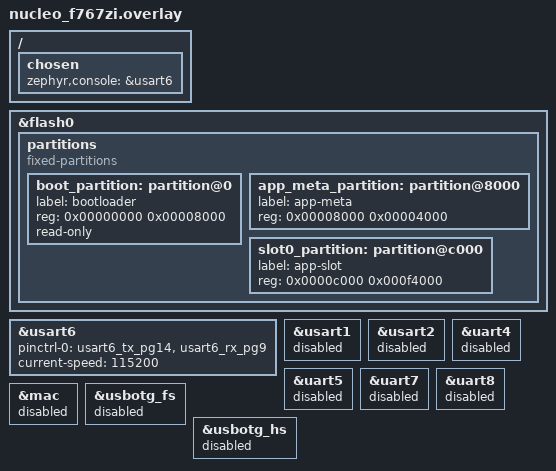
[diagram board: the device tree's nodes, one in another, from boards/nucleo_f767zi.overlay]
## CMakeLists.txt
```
#
# CMakeLists.txt - Zephyr demo application (ZDEMO), NUCLEO-F767ZI
#
# Author:  Sandesh Ghimire <sandesh@soccentric.com>
# Date:    2026-11-03
# SRS:     SRS-ZEPHYR-F767 (ZCON-001..003, ZGEN-001..007, ZLNK-001..004)
#
# Freestanding Zephyr application (ZCON-003): built against $ZEPHYR_BASE in
# the stm32-dev-zephyr container, without a west workspace.
#   scripts/build.sh [clean]
#

cmake_minimum_required(VERSION 3.20.0)

set(BOARD nucleo_f767zi)
set(DTC_OVERLAY_FILE "${CMAKE_CURRENT_SOURCE_DIR}/boards/nucleo_f767zi.overlay")

# --- Version and build metadata (ZGEN-002) ---------------------------------
file(STRINGS "${CMAKE_CURRENT_SOURCE_DIR}/VERSION" VERSION_LINES)
foreach(_line IN LISTS VERSION_LINES)
    if(_line MATCHES "^VERSION_MAJOR[ \t]*=[ \t]*([0-9]+)")
        set(APP_VERSION_MAJOR "${CMAKE_MATCH_1}")
    elseif(_line MATCHES "^VERSION_MINOR[ \t]*=[ \t]*([0-9]+)")
        set(APP_VERSION_MINOR "${CMAKE_MATCH_1}")
    elseif(_line MATCHES "^PATCHLEVEL[ \t]*=[ \t]*([0-9]+)")
        set(APP_VERSION_PATCH "${CMAKE_MATCH_1}")
    endif()
endforeach()
if(NOT DEFINED APP_VERSION_MAJOR)
    set(APP_VERSION_MAJOR 0)
endif()
if(NOT DEFINED APP_VERSION_MINOR)
    set(APP_VERSION_MINOR 1)
endif()
if(NOT DEFINED APP_VERSION_PATCH)
    set(APP_VERSION_PATCH 0)
endif()
set(APP_VERSION "${APP_VERSION_MAJOR}.${APP_VERSION_MINOR}.${APP_VERSION_PATCH}")
set(APP_FIRMWARE_NAME "zephyr-app")

execute_process(COMMAND git -C "${CMAKE_CURRENT_SOURCE_DIR}" rev-parse --short=12 HEAD
    OUTPUT_VARIABLE APP_GIT_COMMIT OUTPUT_STRIP_TRAILING_WHITESPACE ERROR_QUIET)
execute_process(COMMAND git -C "${CMAKE_CURRENT_SOURCE_DIR}" rev-parse HEAD
    OUTPUT_VARIABLE APP_GIT_COMMIT_FULL OUTPUT_STRIP_TRAILING_WHITESPACE ERROR_QUIET)
if(NOT APP_GIT_COMMIT)
    set(APP_GIT_COMMIT "unknown")
    set(APP_GIT_COMMIT_FULL "")
else()
    execute_process(COMMAND git -C "${CMAKE_CURRENT_SOURCE_DIR}" status --porcelain
        OUTPUT_VARIABLE APP_GIT_DIRTY OUTPUT_STRIP_TRAILING_WHITESPACE ERROR_QUIET)
    if(APP_GIT_DIRTY)
        string(APPEND APP_GIT_COMMIT "-dirty")
    endif()
endif()
string(TIMESTAMP APP_BUILD_DATE "%Y-%m-%d %H:%M:%S" UTC)
string(TIMESTAMP APP_BUILD_TIMESTAMP "%s" UTC)

# The image's Zephyr tree has no .git (ZCON-002); its version is recorded in
# /opt/zephyrproject/VERSION by docker/Dockerfile.
if(NOT DEFINED BUILD_VERSION AND EXISTS "$ENV{ZEPHYR_BASE}/../VERSION")
    file(STRINGS "$ENV{ZEPHYR_BASE}/../VERSION" BUILD_VERSION LIMIT_COUNT 1)
endif()

find_package(Zephyr REQUIRED HINTS $ENV{ZEPHYR_BASE})
project(zephyr_app LANGUAGES C)

target_compile_definitions(app PRIVATE
    APP_VERSION_STR="${APP_VERSION}"
    APP_FIRMWARE_NAME="${APP_FIRMWARE_NAME}"
    APP_GIT_COMMIT="${APP_GIT_COMMIT}"
    APP_BUILD_DATE="${APP_BUILD_DATE}"
    APP_BUILD_TIMESTAMP=${APP_BUILD_TIMESTAMP}
    APP_FLATCC_HEAP_SIZE=12288
    FLATCC_ALLOC=app_flatcc_alloc
    FLATCC_FREE=app_flatcc_free
    FLATCC_REALLOC=app_flatcc_realloc
    FLATCC_CALLOC=app_flatcc_calloc
    FLATCC_ALIGNED_ALLOC=app_flatcc_aligned_alloc
    FLATCC_ALIGNED_FREE=app_flatcc_aligned_free
    FLATCC_EMITTER_ALLOC=app_flatcc_alloc
    FLATCC_EMITTER_FREE=app_flatcc_free)

# The generated flatcc headers and runtime see the fixed-arena allocator
# through this force-include (ZRT-004).
target_compile_options(app PRIVATE
    -include "${CMAKE_CURRENT_SOURCE_DIR}/src/comms/flatcc_port.h")

target_include_directories(app PRIVATE
    "${CMAKE_CURRENT_SOURCE_DIR}/src"
    "${CMAKE_BINARY_DIR}/generated"
    "${CMAKE_CURRENT_SOURCE_DIR}/src/generated"
    "${CMAKE_CURRENT_SOURCE_DIR}/third_party/flatcc/include")

# The generated flatcc headers use compact macro formatting that trips
# -Wmisleading-indentation in the one translation unit that includes them.
set_source_files_properties(src/comms/comms.c PROPERTIES
    COMPILE_OPTIONS "-Wno-misleading-indentation")

target_sources(app PRIVATE
    # Application entry point and shared configuration
    src/main.c

    # Board-level I/O
    src/board/button.c
    src/board/led.c

    # Bootloader contract and metadata
    src/boot/flash_confirm.c
    src/boot/handover.c
    src/boot/identity.c

    # HWLINK communication stack
    src/comms/comms.c
    src/comms/flatcc_port.c
    src/comms/hwlink.c
    src/comms/uart_hwlink.c

    # System services and supervision
    src/system/debug_log.c
    src/system/fatal.c
    src/system/health.c
    src/system/iwdg.c
    src/system/reset_cause.c)

# flatcc 0.6.1 runtime as released.  Only builder, verifier and emitter are
# linked; JSON support is not used.
set(FLATCC_ROOT "${CMAKE_CURRENT_SOURCE_DIR}/third_party/flatcc")
target_sources(app PRIVATE
    "${FLATCC_ROOT}/src/runtime/builder.c"
    "${FLATCC_ROOT}/src/runtime/verifier.c"
    "${FLATCC_ROOT}/src/runtime/emitter.c"
    "${FLATCC_ROOT}/src/runtime/refmap.c")

# --- HWLINK schema (ZLNK-001) ------------------------------------------------
# The generated C headers are committed so the container does not need a host
# flatcc compiler.  When flatcc is available, regenerate them as part of the
# build; the build-tree copy takes precedence over src/generated.
find_program(FLATCC flatcc)
if(FLATCC)
    set(FLATCC_OUT "${CMAKE_BINARY_DIR}/generated")
    add_custom_command(
        OUTPUT
            "${FLATCC_OUT}/hwlink_reader.h"
            "${FLATCC_OUT}/hwlink_builder.h"
            "${FLATCC_OUT}/hwlink_verifier.h"
            "${FLATCC_OUT}/flatbuffers_common_reader.h"
            "${FLATCC_OUT}/flatbuffers_common_builder.h"
        COMMAND ${CMAKE_COMMAND} -E make_directory "${FLATCC_OUT}"
        COMMAND ${FLATCC} -a -o "${FLATCC_OUT}" "${CMAKE_CURRENT_SOURCE_DIR}/protocol/hwlink.fbs"
        DEPENDS "${CMAKE_CURRENT_SOURCE_DIR}/protocol/hwlink.fbs"
        COMMENT "Generating HWLINK FlatBuffers C headers")
    add_custom_target(hwlink_schema DEPENDS
        "${FLATCC_OUT}/hwlink_reader.h"
        "${FLATCC_OUT}/hwlink_builder.h"
        "${FLATCC_OUT}/hwlink_verifier.h")
    add_dependencies(app hwlink_schema)
endif()

# --- Build products (ZGEN-001, ZGEN-002) -------------------------------------
find_package(Python3 COMPONENTS Interpreter REQUIRED)
get_filename_component(_compiler_dir "${CMAKE_C_COMPILER}" DIRECTORY)
find_program(SIZE_TOOL NAMES arm-zephyr-eabi-size arm-none-eabi-size
    HINTS "${_compiler_dir}" REQUIRED)

add_custom_target(zephyr_app_outputs ALL
    COMMAND ${CMAKE_COMMAND} -E copy
            "${CMAKE_BINARY_DIR}/zephyr/zephyr.elf"
            "${CMAKE_BINARY_DIR}/zephyr-app.elf"
    COMMAND ${CMAKE_COMMAND} -E copy
            "${CMAKE_BINARY_DIR}/zephyr/zephyr.bin"
            "${CMAKE_BINARY_DIR}/zephyr-app.bin"
    COMMAND ${CMAKE_COMMAND} -E copy
            "${CMAKE_BINARY_DIR}/zephyr/zephyr.hex"
            "${CMAKE_BINARY_DIR}/zephyr-app.hex"
    COMMAND ${CMAKE_COMMAND} -E copy
            "${CMAKE_BINARY_DIR}/zephyr/zephyr.map"
            "${CMAKE_BINARY_DIR}/zephyr-app.map"
    COMMAND ${Python3_EXECUTABLE} "${CMAKE_CURRENT_SOURCE_DIR}/scripts/mkimage.py"
            --input "${CMAKE_BINARY_DIR}/zephyr-app.bin"
            --output "${CMAKE_BINARY_DIR}/zephyr-app.img"
            --version "${APP_VERSION}"
            --commit "${APP_GIT_COMMIT_FULL}"
            --timestamp "${APP_BUILD_TIMESTAMP}"
            --name "${APP_FIRMWARE_NAME}"
    COMMAND ${Python3_EXECUTABLE} "${CMAKE_CURRENT_SOURCE_DIR}/scripts/check_footprint.py"
            --size-tool "${SIZE_TOOL}"
            --max-flash 131072
            --max-ram 65536
            "${CMAKE_BINARY_DIR}/zephyr-app.elf"
    DEPENDS zephyr_final
    BYPRODUCTS
        "${CMAKE_BINARY_DIR}/zephyr-app.elf"
        "${CMAKE_BINARY_DIR}/zephyr-app.bin"
        "${CMAKE_BINARY_DIR}/zephyr-app.hex"
        "${CMAKE_BINARY_DIR}/zephyr-app.map"
        "${CMAKE_BINARY_DIR}/zephyr-app.img"
    COMMENT "Copying zephyr-app.* and generating the BOOT image file")
```

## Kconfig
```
#
# Kconfig - ZDEMO application options
#
# Author:  Sandesh Ghimire <sandesh@soccentric.com>
# Date:    2026-11-03
# Target:  NUCLEO-F767ZI
# SRS:     ZFN-004 (HLT-004)
#

mainmenu "Zephyr demo application (ZDEMO)"

config ZDEMO_FAIL_HEALTH
	bool "Force the pending-slot health check to fail"
	default n
	help
	  Build the equivalent of the C demo's DEMO_FAIL_HEALTH option.  A
	  pending slot never confirms, LD3 fast-blinks, and the watchdog is
	  stopped after 10 s so BOOT can count a failed trial and roll back.

source "Kconfig.zephyr"
```

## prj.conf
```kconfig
# prj.conf - ZDEMO Kconfig
# Author: Sandesh Ghimire <sandesh@soccentric.com>
# SRS:    SRS-ZEPHYR-F767

# ZBT-001: run from the bootloader slot at 0x0800C000, 976 KB.
CONFIG_USE_DT_CODE_PARTITION=n
CONFIG_FLASH_LOAD_OFFSET=0xC000
CONFIG_FLASH_LOAD_SIZE=0xF4000

# ZRT-002: k_event is used for health check-ins.
CONFIG_EVENTS=y

# ZRT-003: 1 kHz kernel tick.
CONFIG_SYS_CLOCK_TICKS_PER_SEC=1000

# ZGEN-003: caches on, as in the C demo.
CONFIG_CACHE_MANAGEMENT=y
CONFIG_ICACHE=y
CONFIG_DCACHE=y

# ZRT-006 / ZSAFE-004: MPU stack guards and assertions.
CONFIG_HW_STACK_PROTECTION=y
CONFIG_ASSERT=y

# ZGEN-006: no warnings.
CONFIG_COMPILER_WARNINGS_AS_ERRORS=y

# LEDs, button and USART3.
CONFIG_GPIO=y
CONFIG_SERIAL=y
CONFIG_UART_INTERRUPT_DRIVEN=y
CONFIG_UART_USE_RUNTIME_CONFIGURE=y

# ZCON-005: USART3 carries HWLINK only.  ZDBG-001: console and log output
# go to USART6 instead (chosen zephyr,console in the board overlay).
CONFIG_CONSOLE=y
CONFIG_UART_CONSOLE=y
CONFIG_PRINTK=y
CONFIG_BOOT_BANNER=n

# ZDBG-002: deferred logging, so no thread waits on the debug UART;
# ZDBG-003: src/system/debug_log.c prints the family line format.
CONFIG_LOG=y
CONFIG_LOG_MODE_DEFERRED=y
CONFIG_LOG_BACKEND_UART=y
CONFIG_LOG_OUTPUT=y
CONFIG_LOG_CUSTOM_FORMAT_SUPPORT=y
CONFIG_LOG_BACKEND_UART_OUTPUT_CUSTOM=y
CONFIG_LOG_DEFAULT_LEVEL=3
CONFIG_LOG_BUFFER_SIZE=1024

# ZGEN-004: fatal errors reset the board.
CONFIG_REBOOT=y

# ZGEN-005: reset cause through hwinfo.
CONFIG_HWINFO=y

# ZBT-006 / ZFN-004: Zephyr flash API for the CONFIRMED record.
CONFIG_FLASH=y

# ZRT-004 / ZFN-004: IWDG through the watchdog API.
CONFIG_WATCHDOG=y

# ZLNK-002: Zephyr CRC32-ISO-HDLC.
CONFIG_CRC=y

# ZRT-005: high-water marks for Status.
CONFIG_THREAD_MONITOR=y
CONFIG_INIT_STACKS=y
CONFIG_THREAD_STACK_INFO=y
CONFIG_THREAD_NAME=y

# Heap statistics for Status (the application itself does not allocate).

# Keep the main thread small; all work is in the static application threads.
CONFIG_MAIN_STACK_SIZE=2048
CONFIG_BOOT_BANNER=n
```

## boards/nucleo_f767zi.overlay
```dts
/*
 * nucleo_f767zi.overlay - NUCLEO-F767ZI flash layout for the project A/B bootloader
 *
 * Author:  Sandesh Ghimire <sandesh@soccentric.com>
 * Date:    2026-11-03
 * Target:  NUCLEO-F767ZI
 * SRS:     ZBT-001, ZBT-006, ZSAFE-001/003, ZDBG-001
 *
 * The board devicetree describes an MCUboot-style layout.  ZDEMO uses the
 * project bootloader layout instead (SRS-BOOT-F767 section 3):
 *
 *   0x08000000  bootloader, sectors 0-1, 32 KB, read-only
 *   0x08008000  metadata, sector 2, 16 KB
 *   0x0800C000  application slot, sectors 3-11, 976 KB
 *
 * Bank swapping maps either bank at 0x08000000, so the same overlay and
 * image work for slot A and slot B.
 */

/delete-node/ &boot_partition;
/delete-node/ &storage_partition;
/delete-node/ &slot0_partition;
/delete-node/ &slot1_partition;
/delete-node/ &scratch_partition;

&flash0 {
	partitions {
		compatible = "fixed-partitions";
		#address-cells = <1>;
		#size-cells = <1>;

		boot_partition: partition@0 {
			label = "bootloader";
			reg = <0x00000000 0x00008000>;
			read-only;
		};

		app_meta_partition: partition@8000 {
			label = "app-meta";
			reg = <0x00008000 0x00004000>;
		};

		slot0_partition: partition@c000 {
			label = "app-slot";
			reg = <0x0000c000 0x000f4000>;
		};
	};
};

/* ZDBG-001: console and log output on USART6 (PG14 = Arduino D1 TX,
 * PG9 = D0 RX), 115200 8N1.  HWLINK keeps USART3 to itself. */
/ {
	chosen {
		zephyr,console = &usart6;
	};
};

&usart6 {
	pinctrl-0 = <&usart6_tx_pg14 &usart6_rx_pg9>;
	pinctrl-names = "default";
	current-speed = <115200>;
	status = "okay";
};

/* ZSAFE-003: only the LEDs, B1, USART3 (HWLINK) and USART6 (debug) are
 * used. */
&usart1 {
	status = "disabled";
};

&usart2 {
	status = "disabled";
};

&uart4 {
	status = "disabled";
};

&uart5 {
	status = "disabled";
};

&uart7 {
	status = "disabled";
};

&uart8 {
	status = "disabled";
};

&mac {
	status = "disabled";
};

&usbotg_fs {
	status = "disabled";
};

&usbotg_hs {
	status = "disabled";
};
```

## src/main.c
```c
/*
 * main.c - Zephyr demo application entry point
 *
 * Author:  Sandesh Ghimire <sandesh@soccentric.com>
 * Date:    2026-11-03
 * Target:  NUCLEO-F767ZI (Zephyr board nucleo_f767zi), started by BOOT
 * SRS:     SRS-ZEPHYR-F767: ZBT-001..005, ZGEN-003..005, ZRT-001..006,
 *          ZFN-001..005, ZSAFE-001..004
 *
 * The four application threads (Health, Comms, Button, LED) are statically
 * defined.  main() only performs the reset-safe early start-up sequence and
 * then returns; Zephyr keeps running the application threads.
 */

#include <soc.h>
#include <zephyr/kernel.h>
#include <zephyr/logging/log.h>

#include "app/zdemo.h"
#include "board/led.h"
#include "boot/boot_contract.h"
#include "boot/handover.h"
#include "comms/uart_hwlink.h"
#include "system/app_fault.h"
#include "system/health.h"
#include "system/iwdg.h"
#include "system/reset_cause.h"

LOG_MODULE_DECLARE(app);

BUILD_ASSERT(CONFIG_FLASH_LOAD_OFFSET == 0xC000,
	     "ZBT-001: the application must be linked at 0x0800C000");
BUILD_ASSERT(CONFIG_FLASH_LOAD_SIZE == 0xF4000,
	     "ZBT-001: the application slot is 976 KB");

/**
 * @brief Report heap usage for Status / health purposes.
 *
 * This application is heapless: flatcc uses a fixed static arena and
 * malloc/free are not linked. Reporting a private unused heap would
 * make the Status and health figures meaningless, so both are reported
 * as zero.
 *
 * @param free_bytes   Receives 0 (no heap).
 * @param min_free_bytes Receives 0 (no heap).
 */
void app_heap_stats(uint32_t *free_bytes, uint32_t *min_free_bytes)
{
	*free_bytes = 0U;
	*min_free_bytes = 0U;
}

/**
 * @brief Zephyr application entry point: early start-up sequence.
 *
 * Performs the reset-safe early start-up only (fault record stamp, early
 * watchdog feed, reset-cause capture, hand-over decode, VTOR check,
 * second watchdog feed, LED error latch, UART bring-up) and then returns;
 * Zephyr keeps the statically defined application threads running.
 *
 * @return 0 on success.
 */
int main(void)
{
	/* The fault record is in no-init RAM; bump its boot id first. */
	app_fault_boot_start();

	/* ZBT-002/APP-004: feed the watchdog BOOT started as early as
	 * possible, before any long initialisation. */
	app_wdt_feed();

	/* ZGEN-005: keep the reset cause for Status, then clear it. */
	app_reset_cause_capture();

	/* ZBT-004: decode the hand-over record before Health starts. */
	app_handover_read();

	/* ZDBG-001: start-up line on the debug UART. */
	LOG_INF("start v%s %s, slot %c %s, reset %s", APP_VERSION_STR,
		APP_GIT_COMMIT,
		g_handover.slot == APP_SLOT_A ? 'A' :
		g_handover.slot == APP_SLOT_B ? 'B' : '?',
		g_handover.trial == 2U ? "on trial" :
		g_handover.trial == 1U ? "confirmed" : "no hand-over",
		app_reset_cause_text);

	/* ZBT-001/ZBT-002: the vector table must be the image's own table. */
	if (SCB->VTOR != (0x08000000UL + CONFIG_FLASH_LOAD_OFFSET)) {
		k_panic();
	}

	(void)app_wdt_init();

	/* LED-005: latch LD3 for the last fault or watchdog reset. */
	if (app_fault_is_valid()) {
		(void)led_post_error(APP_ERROR_FAULT);
		LOG_WRN("last fault recorded before this reset");
	}
	if (app_reset_was_error()) {
		(void)led_post_error(APP_ERROR_WATCHDOG);
	}

	/* COM-001/002: USART3 must be running before the health check. */
	if (!hwlink_uart_init()) {
		k_panic();
	}

	return 0;
}
```

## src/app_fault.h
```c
/*
 * app_fault.h - no-init fault record and fatal paths
 *
 * Author:  Sandesh Ghimire <sandesh@soccentric.com>
 * Date:    2026-11-03
 * Target:  NUCLEO-F767ZI
 * SRS:     ZGEN-004 (DGEN-004), ZSAFE-004
 */

#ifndef ZDEMO_APP_FAULT_H
#define ZDEMO_APP_FAULT_H

#include <stdbool.h>
#include <stdint.h>

/** Magic value ('FAUL') identifying a valid non-volatile fault record. */
#define APP_FAULT_MAGIC          0x4641554CUL  /* "FAUL" */
/** Maximum length (including NUL) of the stored task name. */
#define APP_FAULT_TASK_LEN       16U
/** Maximum length (including NUL) of the stored source file name. */
#define APP_FAULT_FILE_LEN       32U

/**
 * @brief Reason categories for a fatal fault captured by this module.
 *
 * The reason is recorded in @ref app_fault_record_t so the reason can be
 * inspected on the following boot.
 */
typedef enum {
    APP_FAULT_NONE = 0,
    APP_FAULT_HARDFAULT,
    APP_FAULT_MEMMANAGE,
    APP_FAULT_BUSFAULT,
    APP_FAULT_USAGEFAULT,
    APP_FAULT_ASSERT,
    APP_FAULT_STACK_OVERFLOW,
    APP_FAULT_MALLOC_FAILED,
    APP_FAULT_STARTUP
} app_fault_reason_t;

/**
 * @brief No-init persistent record of the last fatal fault.
 *
 * Stored in no-init RAM so the record survives a reset. The \c magic
 * field distinguishes a valid record from power-on garbage.
 *
 * @note Do not reorder members without updating the reader/writer side;
 *       the record is consumed by the boot monitor for diagnostics.
 */
typedef struct {
    uint32_t magic;
    uint32_t reason;
    uint32_t cfsr;
    uint32_t hfsr;
    uint32_t mmfar;
    uint32_t bfar;
    uint32_t pc;
    uint32_t lr;
    uint32_t psr;
    uint32_t line;
    uint32_t boot_id;
    char task[APP_FAULT_TASK_LEN];
    char file[APP_FAULT_FILE_LEN];
} app_fault_record_t;

/** Persistent no-init fault record, shared with the fault capture code. */
extern app_fault_record_t g_app_fault;

/**
 * @brief Called at boot start to stamp this boot into the fault record.
 */
void app_fault_boot_start(void);

/**
 * @brief Check whether the fault record holds a valid (magic-checked) entry.
 *
 * @return true if the record magic is valid, false otherwise.
 */
bool app_fault_is_valid(void);

/**
 * @brief Check whether the recorded fault belongs to the current boot.
 *
 * @return true if the record was written during the running boot.
 */
bool app_fault_is_current_boot(void);

/**
 * @brief Check whether the recorded fault is from the previous boot.
 *
 * @return true if the record was written during the boot before this one.
 */
bool app_fault_is_previous_boot(void);

/**
 * @brief Convert a fault reason into a human-readable string.
 *
 * @param reason Fault reason to convert.
 * @return NUL-terminated, read-only description of @p reason.
 */
const char *app_fault_reason_text(app_fault_reason_t reason);

/**
 * @brief Get the task name stored in the fault record.
 *
 * @return NUL-terminated task name (may be empty).
 */
const char *app_fault_task(void);

/**
 * @brief Get the source file name stored in the fault record.
 *
 * @return NUL-terminated file name (may be empty).
 */
const char *app_fault_file(void);

/**
 * @brief Erase the fault record (clears magic and stored data).
 */
void app_fault_clear(void);

#endif /* ZDEMO_APP_FAULT_H */
```

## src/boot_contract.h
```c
/*
 * boot_contract.h - flash layout, hand-over and metadata contract with BOOT
 *
 * Author:  Sandesh Ghimire <sandesh@soccentric.com>
 * Date:    2026-11-03
 * Target:  STM32F767ZIT6, dual-bank flash (nDBANK = 0)
 * SRS:     DBT-001, DBT-004, DBT-005, DBT-006, HLT-002, DSAFE-002
 *
 * The values in this file mirror SRS-BOOT-F767 LAY-001..LAY-005, HND-003 and
 * Appendix B.  DEMO only ever reads the slot metadata and programs the one
 * CONFIRMED record.
 */

#ifndef BOOT_CONTRACT_H
#define BOOT_CONTRACT_H

#include <stdint.h>

/* LAY-002: every application is linked at the slot offset in bank 1.  BOOT
 * maps the active bank at 0x08000000 with SYSCFG_MEMRMP.SWP_FB, so the same
 * image runs from slot A and slot B. */
/** Base address of the application slot in bank 1 (LAY-002). */
#define APP_SLOT_BASE           0x0800C000UL
/** Size of one application slot: 976 KB. */
#define APP_SLOT_SIZE           0x000F4000UL   /* 976 KB */

/** Size of one flash bank (1 MB). */
#define APP_BANK_SIZE           0x00100000UL
/** Offset of the slot metadata sector within a bank. */
#define APP_META_OFFSET         0x00008000UL
/** Size of the slot metadata sector (16 KB). */
#define APP_META_SIZE           0x00004000UL

/* Physical addresses without bank swap (what BOOT uses while it runs). */
/** Slot A metadata address, physical (no bank swap). */
#define APP_META_A_ADDR         0x08008000UL
/** Slot B metadata address, physical (no bank swap). */
#define APP_META_B_ADDR         0x08108000UL

/* While an application runs, SYSCFG_MEMRMP.SWP_FB maps its own bank to
 * 0x08000000, so its metadata sector is always visible at this alias. */
/** Bank-alias address at which a running app sees its own metadata sector. */
#define APP_RUNNING_META_ADDR   0x08008000UL

/* Appendix B record offsets and magic words (little-endian). */
/** Offset of the metadata header record. */
#define APP_META_HEADER_OFFSET    0x000U
/** Offset of the VERIFIED state record. */
#define APP_META_VERIFIED_OFFSET  0x100U
/** Offset of the ACTIVATED state record. */
#define APP_META_ACTIVATED_OFFSET 0x120U
/** Offset of the CONFIRMED state record (the only one DEMO programs). */
#define APP_META_CONFIRMED_OFFSET 0x140U
/** Offset of the REJECTED state record. */
#define APP_META_REJECTED_OFFSET  0x160U
/** Size of one metadata state record, in bytes. */
#define APP_META_RECORD_SIZE      32U

/** Magic word ('VERI') identifying a VERIFIED record. */
#define APP_META_VERIFIED_MAGIC   0x56455249UL  /* "VERI" */
/** Magic word ('ACTV') identifying an ACTIVATED record. */
#define APP_META_ACTIVATED_MAGIC  0x41435456UL  /* "ACTV" */
/** Magic word ('CONF') identifying a CONFIRMED record. */
#define APP_META_CONFIRMED_MAGIC  0x434F4E46UL  /* "CONF" */
/** Magic word ('REJE') identifying a REJECTED record. */
#define APP_META_REJECTED_MAGIC   0x52454A45UL  /* "REJE" */

/** Absolute address of the CONFIRMED record for a running app. */
#define APP_CONFIRMED_ADDR \
    (APP_RUNNING_META_ADDR + APP_META_CONFIRMED_OFFSET)

/* Hand-over record in RTC_BKP2R (HND-003).  The low 24 bits are the magic
 * and the upper byte carries the slot and trial state:
 *
 *   bits  0..23  magic 0x444E48 (the bytes "HND")
 *   bits 24..25  slot: 1 = A, 2 = B, 0 = unknown
 *   bit  26      trial pending
 *   bits 27..28  trial counter (0..3)
 *
 * The exact packing is private to the BOOT/DEMO pair; BOOT writes the same
 * word.  A missing record (no BOOT) reads as erased/zero and is reported as
 * slot UNKNOWN (DBT-004). */
/** Hand-over magic (bytes "HND") in the low 24 bits of RTC_BKP2R. */
#define APP_HANDOVER_MAGIC        0x00444E48UL  /* bytes "HND", 0 */
/** Mask selecting the 24-bit hand-over magic field. */
#define APP_HANDOVER_MAGIC_MASK   0x00FFFFFFUL
/** Bit shift of the slot field (1 = A, 2 = B) in the hand-over word. */
#define APP_HANDOVER_SLOT_SHIFT   24U
/** Mask of the slot field within its bit pair. */
#define APP_HANDOVER_SLOT_MASK    0x3UL
/** Bit selecting "trial pending" in the hand-over word. */
#define APP_HANDOVER_PENDING_BIT  26U
/** Bit shift of the 2-bit trial counter (0..3). */
#define APP_HANDOVER_TRIAL_SHIFT  27U
/** Mask of the trial counter field within its two bits. */
#define APP_HANDOVER_TRIAL_MASK   0x3UL

/* RTC_BKP1R "stay in BOOT" request (ENT-002). */
/** Magic word (bytes "STAY") in RTC_BKP1R requesting reboot into BOOT. */
#define APP_STAY_IN_BOOT_MAGIC    0x59415453UL  /* bytes "STAY" */

/* Slot identifiers shared with Status. */
/** Slot value meaning "unknown / no hand-over record". */
#define APP_SLOT_UNKNOWN          0U
/** Slot value for flash slot A. */
#define APP_SLOT_A                1U
/** Slot value for flash slot B. */
#define APP_SLOT_B                2U

#endif /* BOOT_CONTRACT_H */
```

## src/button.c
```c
/*
 * button.c - user button B1 (PC13), GPIO interrupt + 30 ms debounce
 *
 * Author:  Sandesh Ghimire <sandesh@soccentric.com>
 * Date:    2026-11-03
 * Target:  NUCLEO-F767ZI
 * SRS:     ZFN-002 (BTN-001..BTN-004)
 *
 * B1 is physically high when pressed.  The GPIO interrupt only wakes the
 * thread; debounce and short/long classification use absolute uptime.  The
 * LED thread owns the pattern state, so this thread posts a button message.
 */

#include <zephyr/device.h>
#include <zephyr/drivers/gpio.h>
#include <zephyr/kernel.h>

#include "button.h"
#include "health.h"
#include "led.h"
#include "zdemo.h"
#include "zdemo_threads.h"

/* Debounce window a raw level must hold before it counts as a change. */
#define BUTTON_DEBOUNCE_MS  30U
/* Presses shorter than this (and released) are reported as short presses. */
#define BUTTON_SHORT_MAX_MS 1000U
/* Presses held at least this long are reported as long presses. */
#define BUTTON_LONG_MS      2000U
/* Interval between button-thread check-ins to the health monitor. */
#define BUTTON_CHECKIN_MS   500U
/* Maximum time the thread sleeps on the wake semaphore. */
#define BUTTON_POLL_MS      10U

/** Device-tree descriptor of the user button (alias sw0). */
static const struct gpio_dt_spec button =
	GPIO_DT_SPEC_GET(DT_ALIAS(sw0), gpios);
/** GPIO callback context for the button interrupt. */
static struct gpio_callback button_cb;
/** Semaphore signalled by the button ISR to wake the thread. */
static K_SEM_DEFINE(button_sem, 0, 1);

/**
 * @brief Read the raw, un-debounced level of the button pin.
 *
 * @return true if the pin reads high (button physically pressed),
 *         false if low.
 */
static bool button_raw(void)
{
	return gpio_pin_get_raw(button.port, button.pin) > 0;
}

/**
 * @brief GPIO interrupt handler for the button.
 *
 * Only wakes the button thread; all debounce and press classification is
 * done in thread context.
 */
static void button_isr(const struct device *port, struct gpio_callback *cb,
		       gpio_port_pins_t pins)
{
	ARG_UNUSED(port);
	ARG_UNUSED(cb);
	ARG_UNUSED(pins);

	k_sem_give(&button_sem);
}

/**
 * @brief Button debounce and short/long press classification thread.
 *
 * Wakes on the button ISR semaphore (with a polling fallback), debounces
 * the raw pin level, and posts a message to the LED thread on release:
 * - short press: release after less than 1 s
 * - long press:  held for at least 2 s (posted once, while held)
 *
 * Also check-ins with the health monitor periodically.
 */
static void button_thread(void *p1, void *p2, void *p3)
{
	ARG_UNUSED(p1);
	ARG_UNUSED(p2);
	ARG_UNUSED(p3);

	(void)k_thread_name_set(k_current_get(), "Button");

	if (!gpio_is_ready_dt(&button) ||
	    gpio_pin_configure_dt(&button, GPIO_INPUT | GPIO_PULL_DOWN) != 0) {
		k_panic();
	}

	gpio_init_callback(&button_cb, button_isr, BIT(button.pin));
	if (gpio_add_callback_dt(&button, &button_cb) != 0 ||
	    gpio_pin_interrupt_configure_dt(&button, GPIO_INT_EDGE_BOTH) != 0) {
		k_panic();
	}

	uint32_t now = k_uptime_get_32();
	bool stable = button_raw();
	bool candidate = stable;
	uint32_t candidate_since = now;
	uint32_t press_start = now;
	bool pressed = stable;
	bool long_sent = false;
	uint32_t last_checkin = now;

	for (;;) {
		(void)k_sem_take(&button_sem, K_MSEC(BUTTON_POLL_MS));
		now = k_uptime_get_32();
		bool raw = button_raw();

		if (raw != candidate) {
			candidate = raw;
			candidate_since = now;
		} else if (candidate != stable &&
			   (now - candidate_since) >= BUTTON_DEBOUNCE_MS) {
			stable = candidate;
			if (stable) {
				pressed = true;
				long_sent = false;
				press_start = now;
			} else {
				uint32_t duration = now - press_start;

				if (pressed && !long_sent) {
					if (duration < BUTTON_SHORT_MAX_MS) {
						(void)led_post_button(1U);
					} else if (duration >= BUTTON_LONG_MS) {
						(void)led_post_button(2U);
					}
				}
				pressed = false;
			}
		}

		if (pressed && !long_sent &&
		    (now - press_start) >= BUTTON_LONG_MS) {
			long_sent = true;
			(void)led_post_button(2U);
		}

		if ((now - last_checkin) >= BUTTON_CHECKIN_MS) {
			health_checkin(HEALTH_TASK_BUTTON);
			last_checkin = now;
		}
	}
}

/* Button thread: debounce + short/long press detection. */
K_THREAD_DEFINE(zdemo_button_thread, ZDEMO_BUTTON_STACK, button_thread, NULL,
		NULL, NULL, ZDEMO_PRIO_BUTTON, 0, 0);
```

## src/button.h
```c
/*
 * button.h - user button B1 (PC13), GPIO interrupt + 30 ms debounce
 *
 * Author:  Sandesh Ghimire <sandesh@soccentric.com>
 * Date:    2026-11-03
 * Target:  NUCLEO-F767ZI
 * SRS:     ZFN-002 (BTN-001..BTN-004)
 */

/**
 * @file button.h
 * @brief Public interface placeholder for user button B1 (PC13).
 *
 * The button driver (implementation in button.c) handles GPIO interrupt
 * and 30 ms debounce internally and communicates with other threads
 * through the LED message queue, so this header currently exposes no
 * public API.
 */
#ifndef ZDEMO_BUTTON_H
#define ZDEMO_BUTTON_H

#endif /* ZDEMO_BUTTON_H */
```

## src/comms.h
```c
/*
 * comms.h - HWLINK Comms thread
 *
 * Author:  Sandesh Ghimire <sandesh@soccentric.com>
 * Date:    2026-11-03
 * Target:  NUCLEO-F767ZI
 * SRS:     ZFN-003 (COM-001..COM-007), ZFN-005
 */

#ifndef ZDEMO_COMMS_H
#define ZDEMO_COMMS_H

#include <stdbool.h>
#include <stdint.h>

bool comms_rx_running(void);
void comms_post_button_event(uint8_t press, uint8_t pattern, uint16_t period);

#endif /* ZDEMO_COMMS_H */
```

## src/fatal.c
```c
/*
 * fatal.c - no-init fault record and the Zephyr fatal error handler
 *
 * Author:  Sandesh Ghimire <sandesh@soccentric.com>
 * Date:    2026-11-03
 * Target:  NUCLEO-F767ZI
 * SRS:     ZGEN-004 (DGEN-004), ZSAFE-004
 *
 * The record lives in Zephyr's .noinit section, so it survives a system
 * reset and can be reported in Status.  The fatal path uses only register
 * accesses and a busy wait; it must work before drivers are up and with
 * interrupts disabled.
 */

#include <soc.h>
#include <zephyr/arch/cpu.h>
#include <zephyr/arch/arm/arch.h>
#include <zephyr/fatal.h>
#include <zephyr/kernel.h>
#include <zephyr/linker/sections.h>
#include <zephyr/sys/reboot.h>

#include "app_fault.h"

/** Persistent no-init fault record (declared in app_fault.h). */
app_fault_record_t g_app_fault __noinit;
/** Monotonic boot counter, survives reset; distinguishes boots. */
static uint32_t app_boot_id __noinit;
/** GPIO port of the fault-indicator LED (LD3). */
#define FAULT_LED_PORT GPIOB
/** Pin of the fault-indicator LED on FAULT_LED_PORT. */
#define FAULT_LED_PIN  14U

/** Human-readable names for each app_fault_reason_t value, in enum order. */
static const char *const fault_reason_names[] = {
	"none",
	"hard_fault",
	"mem_manage",
	"bus_fault",
	"usage_fault",
	"assert",
	"stack_overflow",
	"malloc_failed",
	"startup"
};

/**
 * @brief Copy a string with a fixed destination size (NUL-safe).
 *
 * A NULL source produces an empty string. Always NUL-terminates.
 *
 * @param dst       Destination buffer.
 * @param dst_size  Size of the destination buffer.
 * @param src       Source string, may be NULL.
 */
static void fault_copy(char *dst, uint32_t dst_size, const char *src)
{
	uint32_t i = 0U;

	if (dst_size == 0U) {
		return;
	}
	if (src != NULL) {
		while ((i + 1U) < dst_size && src[i] != '\0') {
			dst[i] = src[i];
			i++;
		}
	}
	dst[i] = '\0';
}

/**
 * @brief Stamp the beginning of a new boot into the fault record state.
 */
void app_fault_boot_start(void)
{
	app_boot_id++;
	if (app_boot_id == 0U) {
		app_boot_id = 1U;
	}
}

/**
 * @brief Check whether the fault record is present and sane.
 *
 * @return true if the magic and reason fields are valid.
 */
bool app_fault_is_valid(void)
{
	return g_app_fault.magic == APP_FAULT_MAGIC &&
	       g_app_fault.reason <= (uint32_t)APP_FAULT_STARTUP;
}

/**
 * @brief Check whether the recorded fault occurred in this boot.
 *
 * @return true if the record's boot id matches the current boot id.
 */
bool app_fault_is_current_boot(void)
{
	return app_fault_is_valid() && g_app_fault.boot_id == app_boot_id;
}

/**
 * @brief Check whether the recorded fault occurred in the previous boot.
 *
 * @return true if the record's boot id is the one before the current.
 */
bool app_fault_is_previous_boot(void)
{
	uint32_t previous = app_boot_id - 1U;

	if (previous == 0U) {
		previous = 0xFFFFFFFFUL;
	}
	return app_fault_is_valid() && g_app_fault.boot_id == previous;
}

/**
 * @brief Human-readable text for a fault reason (never NULL).
 *
 * @param reason Fault reason.
 * @return Read-only name, or "unknown" for out-of-range values.
 */
const char *app_fault_reason_text(app_fault_reason_t reason)
{
	if ((uint32_t)reason >= (sizeof(fault_reason_names) /
				 sizeof(fault_reason_names[0]))) {
		return "unknown";
	}
	return fault_reason_names[reason];
}

/**
 * @brief Task name from the fault record (NUL-terminated).
 *
 * @return Read-only stored task name.
 */
const char *app_fault_task(void)
{
	return g_app_fault.task;
}

/**
 * @brief Source file name from the fault record (NUL-terminated).
 *
 * @return Read-only stored file name.
 */
const char *app_fault_file(void)
{
	return g_app_fault.file;
}

/**
 * @brief Write the full fault record with magic-last ordering.
 *
 * The magic is cleared first so an interrupted write is never mistaken
 * for a complete record.
 */
static void app_fault_save(app_fault_reason_t reason, uint32_t cfsr,
			   uint32_t hfsr, uint32_t mmfar, uint32_t bfar,
			   uint32_t pc, uint32_t lr, uint32_t psr,
			   const char *task, const char *file, uint32_t line)
{
	/* Invalidate first so a reset in the middle of the copy is not
	 * mistaken for a complete record. */
	g_app_fault.magic = 0U;
	__DMB();

	g_app_fault.reason = (uint32_t)reason;
	g_app_fault.cfsr = cfsr;
	g_app_fault.hfsr = hfsr;
	g_app_fault.mmfar = mmfar;
	g_app_fault.bfar = bfar;
	g_app_fault.pc = pc;
	g_app_fault.lr = lr;
	g_app_fault.psr = psr;
	g_app_fault.line = line;
	g_app_fault.boot_id = app_boot_id;
	fault_copy(g_app_fault.task, sizeof(g_app_fault.task), task);
	fault_copy(g_app_fault.file, sizeof(g_app_fault.file), file);

	__DMB();
	g_app_fault.magic = APP_FAULT_MAGIC;
	__DSB();
}

/**
 * @brief Invalidate the fault record (clears the magic).
 */
void app_fault_clear(void)
{
	g_app_fault.magic = 0U;
	__DMB();
}

/**
 * @brief Drive the fault LED (LD3) on or off via raw registers.
 *
 * Works with interrupts disabled and before drivers are up.
 *
 * @param on true to switch the LED on.
 */
static void fault_led3(bool on)
{
	FAULT_LED_PORT->BSRR = on ? (1UL << FAULT_LED_PIN)
				  : ((1UL << FAULT_LED_PIN) << 16U);
}

/**
 * @brief Signal the fatal error on LD3 (three flashes, pause, repeat)
 * and reset the system.
 *
 * Uses only register accesses and k_busy_wait; safe from any context.
 */
static void fault_show_and_reset(void)
{
	__disable_irq();

	/* Register-level LED setup: DGEN-004 must work from any context. */
	RCC->AHB1ENR |= RCC_AHB1ENR_GPIOBEN;
	__DSB();
	uint32_t moder = FAULT_LED_PORT->MODER;

	moder &= ~(3UL << (FAULT_LED_PIN * 2U));
	moder |= (1UL << (FAULT_LED_PIN * 2U));
	FAULT_LED_PORT->MODER = moder;
	__DSB();

	/* Three short flashes, a pause, repeat; roughly 2 s. */
	for (uint32_t cycle = 0U; cycle < 2U; cycle++) {
		for (uint32_t flash = 0U; flash < 3U; flash++) {
			fault_led3(true);
			k_busy_wait(100U * USEC_PER_MSEC);
			fault_led3(false);
			k_busy_wait(100U * USEC_PER_MSEC);
		}
		k_busy_wait(500U * USEC_PER_MSEC);
	}

	sys_reboot(SYS_REBOOT_COLD);
	for (;;) {
		__NOP();
	}
}

/**
 * @brief Map a Zephyr fatal error code to an app fault reason.
 *
 * Zephyr 4.x reports Cortex-M exceptions with arch-specific reasons
 * (K_ERR_ARM_MEM_*, K_ERR_ARM_BUS_*, K_ERR_ARM_USAGE_*), not only
 * K_ERR_CPU_EXCEPTION; unmapped codes default to STARTUP.
 *
 * @param reason Zephyr fatal error code.
 * @return Corresponding app fault reason.
 */
static app_fault_reason_t fatal_reason(unsigned int reason)
{
	/* Zephyr 4.x reports Cortex-M exceptions with arch-specific reasons
	 * (K_ERR_ARM_MEM_*, K_ERR_ARM_BUS_*, K_ERR_ARM_USAGE_*), not only
	 * K_ERR_CPU_EXCEPTION.  Without this mapping every MemManage,
	 * BusFault and UsageFault was saved as "startup" with CFSR=0. */
	if (reason >= K_ERR_ARM_MEM_GENERIC &&
	    reason <= K_ERR_ARM_MEM_FP_LAZY_STATE_PRESERVATION) {
		return APP_FAULT_MEMMANAGE;
	}
	if (reason >= K_ERR_ARM_BUS_GENERIC &&
	    reason <= K_ERR_ARM_BUS_FP_LAZY_STATE_PRESERVATION) {
		return APP_FAULT_BUSFAULT;
	}
	if (reason >= K_ERR_ARM_USAGE_GENERIC &&
	    reason <= K_ERR_ARM_USAGE_UNDEFINED_INSTRUCTION) {
		return reason == K_ERR_ARM_USAGE_STACK_OVERFLOW
			       ? APP_FAULT_STACK_OVERFLOW
			       : APP_FAULT_USAGEFAULT;
	}
	if (reason >= K_ERR_ARM_SECURE_GENERIC &&
	    reason <= K_ERR_ARM_SECURE_LAZY_STATE_ERROR) {
		return APP_FAULT_MEMMANAGE;
	}

	if (reason == K_ERR_CPU_EXCEPTION) {
		uint32_t cfsr = SCB->CFSR;

		if ((cfsr & SCB_CFSR_MEMFAULTSR_Msk) != 0U) {
			return APP_FAULT_MEMMANAGE;
		}
		if ((cfsr & SCB_CFSR_BUSFAULTSR_Msk) != 0U) {
			return APP_FAULT_BUSFAULT;
		}
		if ((cfsr & SCB_CFSR_USGFAULTSR_Msk) != 0U) {
			return APP_FAULT_USAGEFAULT;
		}
		return APP_FAULT_HARDFAULT;
	}

	switch (reason) {
	case K_ERR_STACK_CHK_FAIL:
		return APP_FAULT_STACK_OVERFLOW;
	case K_ERR_KERNEL_OOPS:
	case K_ERR_KERNEL_PANIC:
		return APP_FAULT_ASSERT;
	case K_ERR_SPURIOUS_IRQ:
	default:
		return APP_FAULT_STARTUP;
	}
}

/**
 * @brief Zephyr fatal error handler: save the fault record, flash LD3, reset.
 *
 * Captures the current task name and faulting PC/LR/PSR from the saved
 * frame, stores a no-init fault record, then signals and resets.
 *
 * @param reason Zephyr fatal error code.
 * @param esf    Saved exception frame, may be NULL.
 */
void k_sys_fatal_error_handler(unsigned int reason, const struct arch_esf *esf)
{
	const char *task = "kernel";
	uint32_t pc = 0U;
	uint32_t lr = 0U;
	uint32_t psr = 0U;

	if (k_is_in_isr() == false) {
		const char *name = k_thread_name_get(k_current_get());

		if (name != NULL && name[0] != '\0') {
			task = name;
		}
	}
	if (esf != NULL) {
		pc = esf->basic.pc;
		lr = esf->basic.lr;
		psr = esf->basic.xpsr;
	}

	app_fault_save(fatal_reason(reason), SCB->CFSR, SCB->HFSR,
		       SCB->MMFAR, SCB->BFAR, pc, lr, psr, task, "zephyr", 0U);
	fault_show_and_reset();
}
```

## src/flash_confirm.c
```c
/*
 * flash_confirm.c - program the single CONFIRMED metadata record
 *
 * Author:  Sandesh Ghimire <sandesh@soccentric.com>
 * Date:    2026-11-03
 * Target:  NUCLEO-F767ZI, dual-bank flash
 * SRS:     ZBT-006, ZFN-004 (HLT-002, HLT-005), ZSAFE-001/002
 *
 * Appendix B of SRS-BOOT-F767 defines a 32-byte record: magic in word 0,
 * CRC-32/ISO-HDLC over the first 28 bytes in the last word.  The metadata
 * sector is erased by BOOT before the trial; the application never erases.
 */

#include <soc.h>
#include <string.h>
#include <zephyr/drivers/flash.h>
#include <zephyr/storage/flash_map.h>
#include <zephyr/sys/crc.h>

#include "boot_contract.h"
#include "flash_confirm.h"

/* Number of 32-bit words in one 32-byte CONFIRMED record. */
#define CONFIRMED_WORDS (APP_META_RECORD_SIZE / 4U)

BUILD_ASSERT(PARTITION_ADDRESS(app_meta_partition) == APP_RUNNING_META_ADDR,
	     "app_meta_partition must alias the running slot metadata sector");
BUILD_ASSERT(PARTITION_SIZE(app_meta_partition) == APP_META_SIZE,
	     "app_meta_partition must cover exactly one metadata sector");
BUILD_ASSERT(APP_META_CONFIRMED_OFFSET + APP_META_RECORD_SIZE <= APP_META_SIZE,
	     "CONFIRMED record must lie inside app_meta_partition");

/** Flash device covering the running slot's metadata sector. */
static const struct device *const flash_dev =
	PARTITION_DEVICE(app_meta_partition);
/** Flash offset of the CONFIRMED record within the metadata partition. */
static const off_t record_offset =
	PARTITION_OFFSET(app_meta_partition) + APP_META_CONFIRMED_OFFSET;

/**
 * @brief Invalidate the cache line covering the CONFIRMED record.
 *
 * The STM32F7 flash driver flushes the D-cache for erase but not for a
 * byte-programming write, so every read must first invalidate the one
 * metadata record to see the actual flash contents.
 */
static void record_cache_invalidate(void)
{
	SCB_InvalidateDCache_by_Addr(
		(uint32_t *)(APP_RUNNING_META_ADDR + APP_META_CONFIRMED_OFFSET),
		APP_META_RECORD_SIZE);
}

/**
 * @brief Check CONFIRMED-record magic and trailing CRC-32.
 *
 * @param record Pointer to 8 words of flash data.
 * @return true if magic and CRC are both correct.
 */
static bool record_valid(const uint32_t *record)
{
	if (record[0] != APP_META_CONFIRMED_MAGIC) {
		return false;
	}
	return crc32_ieee((const uint8_t *)record, APP_META_RECORD_SIZE - 4U) ==
	       record[CONFIRMED_WORDS - 1U];
}

/**
 * @brief Check whether the CONFIRMED record is all-erased (0xFF).
 *
 * @param record Pointer to 8 words of flash data.
 * @return true if every word is the erased state.
 */
static bool record_erased(const uint32_t *record)
{
	for (uint32_t i = 0U; i < CONFIRMED_WORDS; i++) {
		if (record[i] != 0xFFFFFFFFUL) {
			return false;
		}
	}
	return true;
}

/**
 * @brief Confirm the running slot by programming the CONFIRMED record.
 *
 * If the record is already valid it is a no-op. If erased, the one fixed
 * record location is programmed (magic + CRC) and verified by re-reading.
 * The application never erases; BOOT erases the metadata sector before
 * a trial.
 *
 * @return true when a valid CONFIRMED record is present afterwards,
 *         false on flash errors or an unexpected (non-erased) record.
 */
bool app_flash_confirm_running_slot(void)
{
	uint32_t record[CONFIRMED_WORDS];

	if (!device_is_ready(flash_dev)) {
		return false;
	}

	record_cache_invalidate();
	if (flash_read(flash_dev, record_offset, record, sizeof(record)) != 0) {
		return false;
	}
	if (record_valid(record)) {
		return true;
	}
	if (!record_erased(record)) {
		return false;
	}

	memset(record, 0, sizeof(record));
	record[0] = APP_META_CONFIRMED_MAGIC;
	record[CONFIRMED_WORDS - 1U] =
		crc32_ieee((const uint8_t *)record, APP_META_RECORD_SIZE - 4U);

	/* ZSAFE-002: the address is fixed here, never supplied by a caller. */
	if (flash_write(flash_dev, record_offset, record, sizeof(record)) != 0) {
		return false;
	}

	record_cache_invalidate();

	uint32_t verify[CONFIRMED_WORDS];

	if (flash_read(flash_dev, record_offset, verify, sizeof(verify)) != 0) {
		return false;
	}
	return record_valid(verify);
}
```

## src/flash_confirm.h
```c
/*
 * flash_confirm.h - program the single CONFIRMED metadata record
 *
 * Author:  Sandesh Ghimire <sandesh@soccentric.com>
 * Date:    2026-11-03
 * Target:  NUCLEO-F767ZI
 * SRS:     ZBT-006, ZFN-004 (HLT-002, HLT-005), ZSAFE-001/002
 */

#ifndef ZDEMO_FLASH_CONFIRM_H
#define ZDEMO_FLASH_CONFIRM_H

#include <stdbool.h>

/* Program CONFIRMED for the running slot if absent. No erase is ever issued. */
bool app_flash_confirm_running_slot(void);

#endif /* ZDEMO_FLASH_CONFIRM_H */
```

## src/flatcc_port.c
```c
/*
 * flatcc_port.c - fixed-arena allocator for the flatcc runtime
 *
 * Author:  Sandesh Ghimire <sandesh@soccentric.com>
 * Date:    2026-11-03
 * Target:  STM32F767ZIT6
 * SRS:     DRT-004 (no allocation after start-up), DCON-002
 *
 * A small first-fit allocator with 16-byte blocks.  It is used only by the
 * Comms task (builder/verifier), so no lock is needed.  The arena is part of
 * .bss; malloc/free are never linked.
 */

#include <string.h>
#include "flatcc_port.h"

/* Total arena size in bytes; override at build time to resize. */
#ifndef APP_FLATCC_HEAP_SIZE
#define APP_FLATCC_HEAP_SIZE (16U * 1024U)
#endif

/* Alignment guaranteed for every block returned from the arena. */
#define FLATCC_ALIGNMENT 16U

/**
 * @brief Header prepended to every arena block.
 *
 * @ref flatcc_arena_t is partitioned into a singly linked list of these
 * blocks; the payload follows the header in memory.
 */
typedef struct flatcc_block {
    size_t size;                 /* payload size */
    struct flatcc_block *next;
    uint32_t free;
    uint32_t pad;
} __attribute__((aligned(FLATCC_ALIGNMENT))) flatcc_block_t;

/**
 * @brief Union view of the static arena, providing natural alignment.
 */
typedef union {
    long double align;
    void *pointer;
    unsigned char bytes[APP_FLATCC_HEAP_SIZE];
} __attribute__((aligned(FLATCC_ALIGNMENT))) flatcc_arena_t;

/** Static .bss arena backing all flatcc allocations. */
static flatcc_arena_t flatcc_arena;
/** Head of the free/used block list (NULL until first use). */
static flatcc_block_t *flatcc_head;

/**
 * @brief Round a size up to the arena block alignment.
 *
 * @param n Requested size.
 * @return Aligned size.
 */
static size_t flatcc_align(size_t n)
{
    return (n + (FLATCC_ALIGNMENT - 1U)) & ~(size_t)(FLATCC_ALIGNMENT - 1U);
}

/**
 * @brief One-shot initialization: seed the arena with a single large free block.
 */
static void flatcc_heap_init(void)
{
    if (flatcc_head == NULL) {
        flatcc_head = (flatcc_block_t *)flatcc_arena.bytes;
        flatcc_head->size = APP_FLATCC_HEAP_SIZE - sizeof(flatcc_block_t);
        flatcc_head->next = NULL;
        flatcc_head->free = 1U;
    }
}

/**
 * @brief First-fit allocation from the flatcc arena (see flatcc_port.h).
 *
 * Splits the chosen block when the leftover can hold a header plus 16
 * payload bytes. Not intended to be called concurrently.
 *
 * @param size Requested size in bytes.
 * @return Pointer to the payload, or NULL if no block is large enough.
 */
void *app_flatcc_alloc(size_t size)
{
    flatcc_heap_init();
    if (size == 0U) {
        return NULL;
    }
    size = flatcc_align(size);

    for (flatcc_block_t *block = flatcc_head; block != NULL;
         block = block->next) {
        if (block->free == 0U || block->size < size) {
            continue;
        }
        /* Split when the tail can hold a header and 16 payload bytes. */
        if ((block->size - size) >= (sizeof(flatcc_block_t) +
                                     FLATCC_ALIGNMENT)) {
            flatcc_block_t *tail = (flatcc_block_t *)((unsigned char *)block +
                                                     sizeof(flatcc_block_t) +
                                                     size);
            tail->size = block->size - size - sizeof(flatcc_block_t);
            tail->next = block->next;
            tail->free = 1U;
            block->next = tail;
            block->size = size;
        }
        block->free = 0U;
        return (unsigned char *)block + sizeof(flatcc_block_t);
    }
    return NULL;
}

/**
 * @brief Return a block to the arena and coalesce with free neighbors.
 *
 * @param ptr Pointer previously returned from the arena, or NULL (no-op).
 */
void app_flatcc_free(void *ptr)
{
    if (ptr == NULL) {
        return;
    }
    flatcc_block_t *block = (flatcc_block_t *)((unsigned char *)ptr -
                                               sizeof(flatcc_block_t));
    block->free = 1U;

    /* Coalesce with a free predecessor, then with free followers. */
    flatcc_block_t *prev = flatcc_head;
    while (prev != NULL && prev->next != block) {
        prev = prev->next;
    }
    if (prev != NULL && prev->free != 0U) {
        prev->size += sizeof(flatcc_block_t) + block->size;
        prev->next = block->next;
        block = prev;
    }
    while (block->next != NULL && block->next->free != 0U) {
        flatcc_block_t *next = block->next;
        block->size += sizeof(flatcc_block_t) + next->size;
        block->next = next->next;
    }
}

/**
 * @brief Resize an arena block.
 *
 * Grows in place when the block is already large enough; otherwise
 * allocates a new block, copies the old contents and frees the old one.
 *
 * @param ptr Existing arena block, or NULL for a fresh allocation.
 * @param size New size in bytes.
 * @return Pointer to the (possibly moved) block, or NULL on failure.
 */
void *app_flatcc_realloc(void *ptr, size_t size)
{
    if (ptr == NULL) {
        return app_flatcc_alloc(size);
    }
    if (size == 0U) {
        app_flatcc_free(ptr);
        return NULL;
    }

    flatcc_block_t *block = (flatcc_block_t *)((unsigned char *)ptr -
                                               sizeof(flatcc_block_t));
    if (block->size >= flatcc_align(size)) {
        return ptr;
    }

    void *new_ptr = app_flatcc_alloc(size);
    if (new_ptr == NULL) {
        return NULL;
    }
    memcpy(new_ptr, ptr, block->size);
    app_flatcc_free(ptr);
    return new_ptr;
}

/**
 * @brief Zero-initialized arena allocation with overflow check.
 *
 * @param count Number of elements.
 * @param size  Size of each element in bytes.
 * @return Zeroed pointer, or NULL on overflow or arena exhaustion.
 */
void *app_flatcc_calloc(size_t count, size_t size)
{
    if (count != 0U && size > (SIZE_MAX / count)) {
        return NULL;
    }
    size_t total = count * size;
    void *ptr = app_flatcc_alloc(total);
    if (ptr != NULL) {
        memset(ptr, 0, total);
    }
    return ptr;
}

/**
 * @brief Aligned arena allocation (the arena already returns 16-byte aligned blocks).
 *
 * @param alignment Requested alignment (ignored, see note).
 * @param size      Requested size in bytes.
 * @return Aligned pointer, or NULL on exhaustion.
 */
void *app_flatcc_aligned_alloc(size_t alignment, size_t size)
{
    (void)alignment;   /* the arena always returns 16-byte aligned blocks */
    return app_flatcc_alloc(size);
}

/**
 * @brief Release an aligned arena block; delegates to app_flatcc_free().
 *
 * @param ptr Pointer from app_flatcc_aligned_alloc(), or NULL (no-op).
 */
void app_flatcc_aligned_free(void *ptr)
{
    app_flatcc_free(ptr);
}
```
